AUTOSAR XML (schema 4-2-2)
package /Components
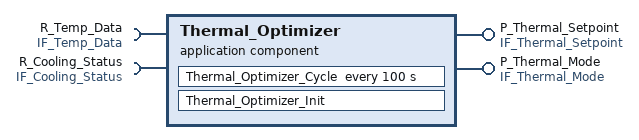
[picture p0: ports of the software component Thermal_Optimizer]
  application sw component type Thermal_Optimizer
    provide port P_Thermal_Setpoint: provided-interface=IF_Thermal_Setpoint
    provide port P_Thermal_Mode: provided-interface=IF_Thermal_Mode
    require port R_Temp_Data: required-interface=IF_Temp_Data
    require port R_Cooling_Status: required-interface=IF_Cooling_Status
    behavior Thermal_Optimizer_InternalBehavior
      init event Thermal_Optimizer_Init_Event: start-on-event=Thermal_Optimizer_Init
      timing event Thermal_Optimizer_Periodic_100ms: start-on-event=Thermal_Optimizer_Cycle, period=100
      runnable Thermal_Optimizer_Init
        data-read-access:
          5 x access:
            VA_Read_t_battery_pack_Init: accessed-variable=R_Temp_Data.t_battery_pack
            VA_Read_t_cabin_ambient_Init: accessed-variable=R_Temp_Data.t_cabin_ambient
            VA_Read_motor_status_Init: accessed-variable=R_Cooling_Status.motor_cooling_status
            VA_Read_battery_status_Init: accessed-variable=R_Cooling_Status.battery_cooling_status
            VA_Read_cabin_status_Init: accessed-variable=R_Cooling_Status.cabin_cooling_status
        data-send-points:
          access VA_Send_target_motor_flow_Init: accessed-variable=P_Thermal_Setpoint.target_motor_coolant_flow
          access VA_Send_target_battery_flow_Init: accessed-variable=P_Thermal_Setpoint.target_battery_coolant_flow
          access VA_Send_target_cabin_duty_Init: accessed-variable=P_Thermal_Setpoint.target_cabin_evap_duty
        data-write-access:
          access VA_Write_target_motor_flow_Init: accessed-variable=P_Thermal_Setpoint.target_motor_coolant_flow
          access VA_Write_target_battery_flow_Init: accessed-variable=P_Thermal_Setpoint.target_battery_coolant_flow
          access VA_Write_target_cabin_duty_Init: accessed-variable=P_Thermal_Setpoint.target_cabin_evap_duty
        mode switch point MSP_Set_Mode_Init: mode-group=P_Thermal_Mode.ThermalModeGroup
      runnable Thermal_Optimizer_Cycle: minimum-start-interval=100
        data-read-access:
          15 x access:
            VA_Read_t_motor: accessed-variable=R_Temp_Data.t_motor
            VA_Read_t_inverter: accessed-variable=R_Temp_Data.t_inverter
            VA_Read_t_battery_pack: accessed-variable=R_Temp_Data.t_battery_pack
            VA_Read_t_batt_coolant_in: accessed-variable=R_Temp_Data.t_batt_coolant_in
            VA_Read_t_batt_coolant_out: accessed-variable=R_Temp_Data.t_batt_coolant_out
            VA_Read_t_cabin_ambient: accessed-variable=R_Temp_Data.t_cabin_ambient
            VA_Read_t_evap_outlet: accessed-variable=R_Temp_Data.t_evap_outlet
            VA_Read_t_heater_core: accessed-variable=R_Temp_Data.t_heater_core
            VA_Read_t_radiator_outlet: accessed-variable=R_Temp_Data.t_radiator_outlet
            VA_Read_t_pump{1..3}_housing: accessed-variable=R_Temp_Data.t_pump{1..3}_housing
            VA_Read_motor_status: accessed-variable=R_Cooling_Status.motor_cooling_status
            VA_Read_battery_status: accessed-variable=R_Cooling_Status.battery_cooling_status
            VA_Read_cabin_status: accessed-variable=R_Cooling_Status.cabin_cooling_status
        data-send-points:
          access VA_Send_target_motor_flow_Cycle: accessed-variable=P_Thermal_Setpoint.target_motor_coolant_flow
          access VA_Send_target_battery_flow_Cycle: accessed-variable=P_Thermal_Setpoint.target_battery_coolant_flow
          access VA_Send_target_cabin_duty_Cycle: accessed-variable=P_Thermal_Setpoint.target_cabin_evap_duty
        data-write-access:
          access VA_Write_target_motor_flow_Cycle: accessed-variable=P_Thermal_Setpoint.target_motor_coolant_flow
          access VA_Write_target_battery_flow_Cycle: accessed-variable=P_Thermal_Setpoint.target_battery_coolant_flow
          access VA_Write_target_cabin_duty_Cycle: accessed-variable=P_Thermal_Setpoint.target_cabin_evap_duty
        mode switch point MSP_Update_Mode_Cycle: mode-group=P_Thermal_Mode.ThermalModeGroup
